# AT91SAM9M11 register map
Vendor: Atmel; Series: SAM9M; File version: 20130207
Atmel AT91SAM9M11 device: ARM926EJ Embedded Microprocessor Unit, 400MHz, Hardware Encryption, Video Decoder, DDR2/LPDDR, Dual EBI, 324 Pins (refer to http://www.atmel.com/devices/SAM9M11.aspx for more)
Registers are 32-bit, read-write, reset 0x0 unless marked. A register's access mark holds for its fields unless they carry their own. Offsets are from the block's base; lines under a group give offsets from that group; [hi:lo] are bit positions; {n}, {i} and the like mark numbered series; 'fields as' and 'values as' point back to an identical list; <NAME> marks a mode.

## Memory map
0x00500000 LCDC size 0x100000 — LCD Controller
0x00900000 VDEC size 0x100000 — Video Decoder
0xFFF78000 UDPHS size 0x4000 — USB High Speed Device Port
0xFFF7C000 TC0 size 0x4000 — Timer Counter 0
0xFFF80000 HSMCI0 size 0x4000 — High Speed MultiMedia Card Interface 0
0xFFF84000 TWI0 size 0x4000 — Two-wire Interface 0
0xFFF88000 TWI1 size 0x4000 — Two-wire Interface 1
0xFFF8C000 USART0 size 0x4000 — Universal Synchronous Asynchronous Receiver Transmitter 0
0xFFF90000 USART1 size 0x4000 — Universal Synchronous Asynchronous Receiver Transmitter 1
0xFFF94000 USART2 size 0x4000 — Universal Synchronous Asynchronous Receiver Transmitter 2
0xFFF98000 USART3 size 0x4000 — Universal Synchronous Asynchronous Receiver Transmitter 3
0xFFF9C000 SSC0 size 0x4000 — Synchronous Serial Controller 0
0xFFFA0000 SSC1 size 0x4000 — Synchronous Serial Controller 1
0xFFFA4000 SPI0 size 0x4000 — Serial Peripheral Interface 0
0xFFFA8000 SPI1 size 0x4000 — Serial Peripheral Interface 1
0xFFFAC000 AC97C size 0x4000 — AC97 Controller
0xFFFB0000 TSADCC size 0x4000 — Touch Screen ADC Controller
0xFFFB4000 ISI size 0x4000 — Image Sensor Interface
0xFFFB8000 PWM size 0x4000 — Pulse Width Modulation Controller
0xFFFBC000 EMAC size 0x4000 — Ethernet MAC 10/100
0xFFFC0000 AES size 0x4000 — Advanced Encryption Standard
0xFFFC4000 TDES size 0x4000 — Triple Data Encryption Standard
0xFFFC8000 SHA size 0x4000 — Secure Hash Algorithm
0xFFFCC000 TRNG size 0x4000 — True Random Number Generator
0xFFFD0000 HSMCI1 size 0x4000 — High Speed MultiMedia Card Interface 1
0xFFFD4000 TC1 size 0x4000 — Timer Counter 1
0xFFFFE400 DDRSDRC1 size 0x200 — DDR_SDR SDRAM Controller 1
0xFFFFE600 DDRSDRC0 size 0x200 — DDR_SDR SDRAM Controller 0
0xFFFFE800 SMC size 0x200 — Static Memory Controller
0xFFFFEA00 MATRIX size 0x200 — AHB Bus Matrix
0xFFFFEC00 DMAC size 0x200 — DMA Controller
0xFFFFEE00 DBGU size 0x200 — Debug Unit
0xFFFFF000 AIC size 0x200 — Advanced Interrupt Controller
0xFFFFF200 PIOA size 0x200 — Parallel Input/Output Controller A
0xFFFFF400 PIOB size 0x200 — Parallel Input/Output Controller B
0xFFFFF600 PIOC size 0x200 — Parallel Input/Output Controller C
0xFFFFF800 PIOD size 0x200 — Parallel Input/Output Controller D
0xFFFFFA00 PIOE size 0x200 — Parallel Input/Output Controller E
0xFFFFFC00 PMC size 0x100 — Power Management Controller
0xFFFFFD00 RSTC size 0x200 — Reset Controller
0xFFFFFD10 SHDWC size 0x200 — Shutdown Controller
0xFFFFFD20 RTT size 0x200 — Real-time Timer
0xFFFFFD30 PIT size 0x200 — Periodic Interval Timer
0xFFFFFD40 WDT size 0x200 — Watchdog Timer
0xFFFFFD60 GPBR size 0x200 — General Purpose Backup Register
0xFFFFFDB0 RTC size 0x30 — Real-time Clock

## Interrupts
0 FIQ (AIC)
1 DDRSDRC0
2 PIOA
3 PIOB
4 PIOC
5 PIOD
6 TRNG
7 USART0
8 USART1
9 USART2
10 USART3
11 HSMCI0
12 TWI0
13 TWI1
14 SPI0
15 SPI1
16 SSC0
17 SSC1
18 TC0
19 PWM
20 TSADCC
21 DMAC
23 LCDC
24 AC97C
25 EMAC
26 ISI
27 UDPHS
28 AES
29 HSMCI1
30 VDEC
31 IRQ (AIC)

## PWM — Pulse Width Modulation Controller
Base 0xFFFB8000; register names take the prefix PWM_
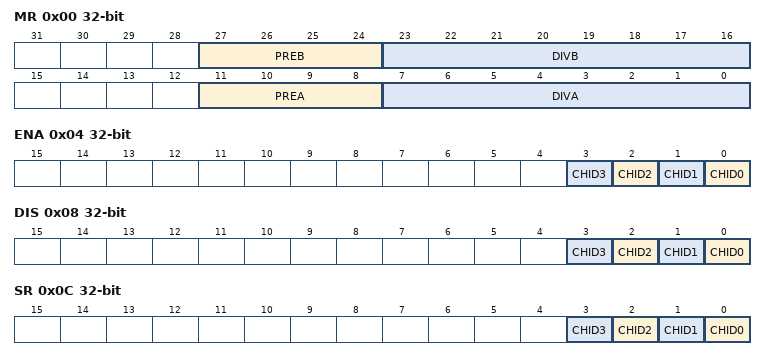
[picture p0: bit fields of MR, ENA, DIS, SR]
0x00 MR — PWM Mode Register
  [27:24] PREB
    0=MCK (Master Clock); 1=MCKDIV2 (Master Clock divided by 2); 2=MCKDIV4 (Master Clock divided by 4); 3=MCKDIV8 (Master Clock divided by 8); 4=MCKDIV16 (Master Clock divided by 16); 5=MCKDIV32 (Master Clock divided by 32); 6=MCKDIV64 (Master Clock divided by 64); 7=MCKDIV128 (Master Clock divided by 128); 8=MCKDIV256 (Master Clock divided by 256); 9=MCKDIV512 (Master Clock divided by 512); 10=MCKDIV1024 (Master Clock divided by 1024)
  [23:16] DIVB — CLKA, CLKB Divide Factor
    0=CLK_OFF (CLKA, CLKB clock is turned off); 1=CLK_DIV1 (CLKA, CLKB clock is clock selected by PREA, PREB)
  [11:8] PREA
    values as PREB
  [7:0] DIVA — CLKA, CLKB Divide Factor
    values as DIVB
0x04 ENA wo reset not defined — PWM Enable Register
  [n] CHID{n} (n=0..3) — Channel ID
0x08 DIS wo reset not defined — PWM Disable Register
  [n] CHID{n} (n=0..3) — Channel ID
0x0C SR ro — PWM Status Register
  [n] CHID{n} (n=0..3) — Channel ID
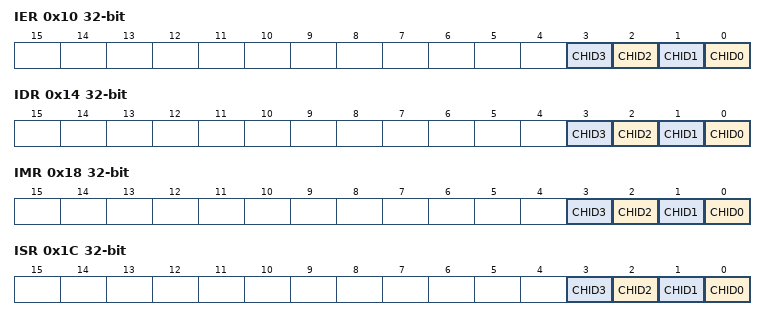
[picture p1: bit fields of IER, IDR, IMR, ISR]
0x10 IER wo reset not defined — PWM Interrupt Enable Register
  [n] CHID{n} (n=0..3) — Channel ID.
0x14 IDR wo reset not defined — PWM Interrupt Disable Register
  [n] CHID{n} (n=0..3) — Channel ID.
0x18 IMR ro — PWM Interrupt Mask Register
  [n] CHID{n} (n=0..3) — Channel ID.
0x1C ISR ro — PWM Interrupt Status Register
  [n] CHID{n} (n=0..3) — Channel ID
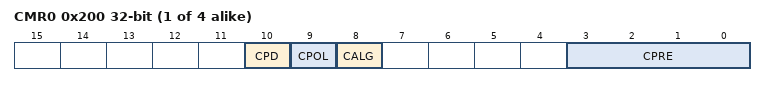
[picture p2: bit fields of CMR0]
{0x200+0x20*i} CMR{i} (i=0..3) — PWM Channel Mode Register (ch_num = {i})
  [10] CPD — Channel Update Period
  [9] CPOL — Channel Polarity
  [8] CALG — Channel Alignment
  [3:0] CPRE — Channel Pre-scaler
    0=MCK (Master Clock); 1=MCKDIV2 (Master Clock divided by 2); 2=MCKDIV4 (Master Clock divided by 4); 3=MCKDIV8 (Master Clock divided by 8); 4=MCKDIV16 (Master Clock divided by 16); 5=MCKDIV32 (Master Clock divided by 32); 6=MCKDIV64 (Master Clock divided by 64); 7=MCKDIV128 (Master Clock divided by 128); 8=MCKDIV256 (Master Clock divided by 256); 9=MCKDIV512 (Master Clock divided by 512); 10=MCKDIV1024 (Master Clock divided by 1024); 11=CLKA (Clock A); 12=CLKB (Clock B)
{0x204+0x20*i} CDTY{i} (i=0..3) — PWM Channel Duty Cycle Register (ch_num = {i})
  [31:0] CDTY — Channel Duty Cycle
{0x208+0x20*i} CPRD{i} (i=0..3) — PWM Channel Period Register (ch_num = {i})
  [31:0] CPRD — Channel Period
{0x20C+0x20*i} CCNT{i} ro (i=0..3) — PWM Channel Counter Register (ch_num = {i})
  [31:0] CNT — Channel Counter Register
{0x210+0x20*i} CUPD{i} wo reset not defined (i=0..3) — PWM Channel Update Register (ch_num = {i})
  [31:0] CUPD

## Notices in the file
SAM Software Package License
Copyright (c) 2013, Atmel Corporation
All rights reserved.
Redistribution and use in source and binary forms, with or without
modification, are permitted provided that the following condition is met:
- Redistributions of source code must retain the above copyright notice,
this list of conditions and the disclaimer below.
Atmel's name may not be used to endorse or promote products derived from
this software without specific prior written permission.
DISCLAIMER:  THIS SOFTWARE IS PROVIDED BY ATMEL "AS IS" AND ANY EXPRESS OR
IMPLIED WARRANTIES, INCLUDING, BUT NOT LIMITED TO, THE IMPLIED WARRANTIES OF
MERCHANTABILITY, FITNESS FOR A PARTICULAR PURPOSE AND NON-INFRINGEMENT ARE
DISCLAIMED. IN NO EVENT SHALL ATMEL BE LIABLE FOR ANY DIRECT, INDIRECT,
INCIDENTAL, SPECIAL, EXEMPLARY, OR CONSEQUENTIAL DAMAGES (INCLUDING, BUT NOT
LIMITED TO, PROCUREMENT OF SUBSTITUTE GOODS OR SERVICES; LOSS OF USE, DATA,
OR PROFITS; OR BUSINESS INTERRUPTION) HOWEVER CAUSED AND ON ANY THEORY OF
LIABILITY, WHETHER IN CONTRACT, STRICT LIABILITY, OR TORT (INCLUDING
NEGLIGENCE OR OTHERWISE) ARISING IN ANY WAY OUT OF THE USE OF THIS SOFTWARE,
EVEN IF ADVISED OF THE POSSIBILITY OF SUCH DAMAGE.
